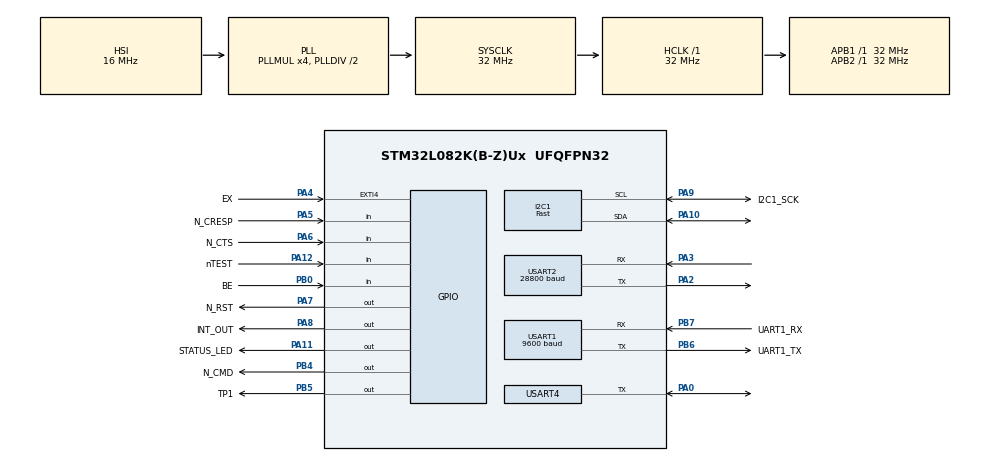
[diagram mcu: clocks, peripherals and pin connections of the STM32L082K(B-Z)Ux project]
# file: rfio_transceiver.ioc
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Dma.Request0=USART1_TX
Dma.Request1=USART1_RX
Dma.USART1_RX.1.Direction=DMA_PERIPH_TO_MEMORY
Dma.USART1_RX.1.Instance=DMA1_Channel3
Dma.USART1_RX.1.MemDataAlignment=DMA_MDATAALIGN_BYTE
Dma.USART1_RX.1.MemInc=DMA_MINC_ENABLE
Dma.USART1_RX.1.Mode=DMA_CIRCULAR
Dma.USART1_RX.1.PeriphDataAlignment=DMA_PDATAALIGN_BYTE
Dma.USART1_RX.1.PeriphInc=DMA_PINC_DISABLE
Dma.USART1_RX.1.Priority=DMA_PRIORITY_LOW
Dma.USART1_TX.0.Direction=DMA_MEMORY_TO_PERIPH
Dma.USART1_TX.0.Instance=DMA1_Channel2
Dma.USART1_TX.0.MemDataAlignment=DMA_MDATAALIGN_BYTE
Dma.USART1_TX.0.MemInc=DMA_MINC_ENABLE
Dma.USART1_TX.0.Mode=DMA_NORMAL
Dma.USART1_TX.0.PeriphDataAlignment=DMA_PDATAALIGN_BYTE
Dma.USART1_TX.0.PeriphInc=DMA_PINC_DISABLE
Dma.USART1_TX.0.Priority=DMA_PRIORITY_LOW
I2C1.DualAddressMode=I2C_DUALADDRESS_ENABLE
I2C1.I2C_Speed_Mode=I2C_Fast
I2C1.OwnAddress=PRIMARY_SLAVE_ADDR
I2C1.OwnAddress2=ENUM_SLAVE_ADDR
I2C1.Timing=0x00300F38
IWDG.Prescaler=IWDG_PRESCALER_256
Mcu.Family=STM32L0
Mcu.Name=STM32L082K(B-Z)Ux
Mcu.Package=UFQFPN32
Mcu.UserConstants=ENUM_SLAVE_ADDR,0x7F;PRIMARY_SLAVE_ADDR,0x44
NVIC.DMA1_Channel2_3_IRQn=true\:0\:0\:false\:false\:true\:false\:true\:true
NVIC.EXTI4_15_IRQn=true\:1\:0\:true\:false\:true\:true\:true\:true
NVIC.I2C1_IRQn=true\:0\:0\:false\:false\:true\:true\:true\:true
NVIC.TIM21_IRQn=true\:0\:0\:false\:false\:true\:true\:true\:true
NVIC.TIM2_IRQn=true\:0\:0\:false\:false\:true\:true\:true\:true
NVIC.USART1_IRQn=true\:2\:0\:true\:false\:true\:true\:true\:true
NVIC.USART2_IRQn=true\:0\:0\:false\:false\:true\:true\:true\:true
NVIC.USART4_5_IRQn=true\:0\:0\:false\:false\:true\:true\:true\:true
PA0.GPIO_ModeDefaultOD=GPIO_MODE_AF_PP
PA0.GPIO_PuPdOD=GPIO_NOPULL
PA0.Mode=Half_duplex(single_wire_mode)
PA0.Signal=USART4_TX
PA10.Mode=I2C
PA10.Signal=I2C1_SDA
PA11.GPIO_Label=STATUS_LED
PA11.Signal=GPIO_Output
PA12.GPIO_Label=nTEST
PA12.Signal=GPIO_Input
PA13.GPIO_Label=STM_SWDIO
PA13.Mode=Serial_Wire
PA13.Signal=SYS_SWDIO
PA14.Mode=Serial_Wire
PA14.Signal=SYS_SWCLK
PA2.Mode=Asynchronous
PA2.Signal=USART2_TX
PA3.Mode=Asynchronous
PA3.Signal=USART2_RX
PA4.GPIO_Label=EX
PA4.Signal=GPXTI4
PA5.GPIO_Label=N_CRESP
PA5.Signal=GPIO_Input
PA6.GPIO_Label=N_CTS
PA6.Signal=GPIO_Input
PA7.GPIO_Label=N_RST
PA7.Signal=GPIO_Output
PA8.GPIO_Label=INT_OUT
PA8.Signal=GPIO_Output
PA9.GPIO_Label=I2C1_SCK
PA9.Mode=I2C
PA9.Signal=I2C1_SCL
PB0.GPIO_Label=BE
PB0.Signal=GPIO_Input
PB4.GPIO_Label=N_CMD
PB4.Signal=GPIO_Output
PB5.GPIO_Label=TP1
PB5.GPIO_Speed=GPIO_SPEED_FREQ_VERY_HIGH
PB5.Signal=GPIO_Output
PB6.GPIO_Label=UART1_TX
PB6.Mode=Asynchronous
PB6.Signal=USART1_TX
PB7.GPIO_Label=UART1_RX
PB7.Mode=Asynchronous
PB7.Signal=USART1_RX
ProjectManager.HeapSize=0x400
ProjectManager.StackSize=0x800
ProjectManager.TargetToolchain=STM32CubeIDE
RCC.AHBFreq_Value=32000000
RCC.APB1Freq_Value=32000000
RCC.APB1TimFreq_Value=32000000
RCC.APB2Freq_Value=32000000
RCC.APB2TimFreq_Value=32000000
RCC.HCLKFreq_Value=32000000
RCC.HSI16_VALUE=16000000
RCC.HSI48_VALUE=48000000
RCC.HSI_VALUE=16000000
RCC.LSE_VALUE=32768
RCC.MSIClockRange=RCC_MSIRANGE_6
RCC.MSI_VALUE=4194000
RCC.PLLMUL=RCC_PLLMUL_4
RCC.SYSCLKFreq_VALUE=32000000
RCC.SYSCLKSource=RCC_SYSCLKSOURCE_PLLCLK
RCC.VCOOutputFreq_Value=64000000
TIM2.Channel-Output\ Compare1\ No\ Output=TIM_CHANNEL_1
TIM2.Period=32000 - 1
TIM21.Channel-Output\ Compare1\ No\ Output=TIM_CHANNEL_1
TIM21.Period=3333 - 1
USART1.BaudRate=9600
USART1.VirtualMode-Asynchronous=VM_ASYNC
USART2.BaudRate=28800
USART2.VirtualMode-Asynchronous=VM_ASYNC
USART4.VirtualMode=VM_ASYNC
VP_CRC_VS_CRC.Mode=CRC_Activate
VP_IWDG_VS_IWDG.Mode=IWDG_Activate
VP_TIM21_VS_ClockSourceINT.Mode=Internal
VP_TIM21_VS_no_output1.Mode=Output Compare1 No Output
VP_TIM2_VS_ClockSourceINT.Mode=Internal
VP_TIM2_VS_no_output1.Mode=Output Compare1 No Output
board=custom

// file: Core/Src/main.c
/* USER CODE BEGIN Header */
/**
  ******************************************************************************
  * @file           : main.c
  * @brief          : Main program body
  ******************************************************************************
  * @attention
  *
  * Copyright (c) 2025 STMicroelectronics.
  * All rights reserved.
  *
  * This software is licensed under terms that can be found in the LICENSE file
  * in the root directory of this software component.
  * If no LICENSE file comes with this software, it is provided AS-IS.
  *
  ******************************************************************************
  */
/* USER CODE END Header */
#include "main.h"

/* USER CODE BEGIN Includes */
#include "rfio_driver.h"
#include "Scheduler/Scheduler.h"
#include "Module_Bus_Driver.h"
/* USER CODE END Includes */

CRC_HandleTypeDef hcrc;

I2C_HandleTypeDef hi2c1;

IWDG_HandleTypeDef hiwdg;

TIM_HandleTypeDef htim2;
TIM_HandleTypeDef htim21;

UART_HandleTypeDef huart1;
UART_HandleTypeDef huart2;
UART_HandleTypeDef huart4;
DMA_HandleTypeDef hdma_usart1_tx;
DMA_HandleTypeDef hdma_usart1_rx;

/* USER CODE BEGIN PV */
const Firmware_Version FWVer = {1, 0, 0, 0};
const uint8_t Primary_Slave_Addr = PRIMARY_SLAVE_ADDR;
/* USER CODE END PV */

void SystemClock_Config(void);
static void MX_GPIO_Init(void);
static void MX_DMA_Init(void);
static void MX_CRC_Init(void);
static void MX_I2C1_Init(void);
static void MX_IWDG_Init(void);
static void MX_TIM2_Init(void);
static void MX_TIM21_Init(void);
static void MX_USART2_UART_Init(void);
static void MX_USART1_UART_Init(void);
static void MX_USART4_UART_Init(void);

int main(void)
{

  /* MCU Configuration--------------------------------------------------------*/

  /* Reset of all peripherals, Initializes the Flash interface and the Systick. */
  HAL_Init();

  /* Configure the system clock */
  SystemClock_Config();

  /* Initialize all configured peripherals */
  MX_GPIO_Init();
  MX_DMA_Init();
  MX_CRC_Init();
  MX_I2C1_Init();
  MX_IWDG_Init();
  MX_TIM2_Init();
  MX_TIM21_Init();
  MX_USART2_UART_Init();
  MX_USART1_UART_Init();
  MX_USART4_UART_Init();
  /* USER CODE BEGIN 2 */
  Start_Scheduler();
  Init_RFIO();
  HAL_TIM_Base_Start_IT(&htim2);
  HAL_TIM_Base_Start_IT(&htim21);
  /* USER CODE END 2 */

  /* Infinite loop */
  while (1)
  {
    Run_Scheduler_Tasks();
    Module_Bus_Tasks();
  }
}

void SystemClock_Config(void)
{
  RCC_OscInitTypeDef RCC_OscInitStruct = {0};
  RCC_ClkInitTypeDef RCC_ClkInitStruct = {0};
  RCC_PeriphCLKInitTypeDef PeriphClkInit = {0};

  /** Configure the main internal regulator output voltage
  */
  __HAL_PWR_VOLTAGESCALING_CONFIG(PWR_REGULATOR_VOLTAGE_SCALE1);

  /** Initializes the RCC Oscillators according to the specified parameters
  * in the RCC_OscInitTypeDef structure.
  */
  RCC_OscInitStruct.OscillatorType = RCC_OSCILLATORTYPE_HSI|RCC_OSCILLATORTYPE_LSI;
  RCC_OscInitStruct.HSIState = RCC_HSI_ON;
  RCC_OscInitStruct.HSICalibrationValue = RCC_HSICALIBRATION_DEFAULT;
  RCC_OscInitStruct.LSIState = RCC_LSI_ON;
  RCC_OscInitStruct.PLL.PLLState = RCC_PLL_ON;
  RCC_OscInitStruct.PLL.PLLSource = RCC_PLLSOURCE_HSI;
  RCC_OscInitStruct.PLL.PLLMUL = RCC_PLLMUL_4;
  RCC_OscInitStruct.PLL.PLLDIV = RCC_PLLDIV_2;
  if (HAL_RCC_OscConfig(&RCC_OscInitStruct) != HAL_OK)
  {
    Error_Handler();
  }

  /** Initializes the CPU, AHB and APB buses clocks
  */
  RCC_ClkInitStruct.ClockType = RCC_CLOCKTYPE_HCLK|RCC_CLOCKTYPE_SYSCLK
                              |RCC_CLOCKTYPE_PCLK1|RCC_CLOCKTYPE_PCLK2;
  RCC_ClkInitStruct.SYSCLKSource = RCC_SYSCLKSOURCE_PLLCLK;
  RCC_ClkInitStruct.AHBCLKDivider = RCC_SYSCLK_DIV1;
  RCC_ClkInitStruct.APB1CLKDivider = RCC_HCLK_DIV1;
  RCC_ClkInitStruct.APB2CLKDivider = RCC_HCLK_DIV1;

  if (HAL_RCC_ClockConfig(&RCC_ClkInitStruct, FLASH_LATENCY_1) != HAL_OK)
  {
    Error_Handler();
  }
  PeriphClkInit.PeriphClockSelection = RCC_PERIPHCLK_USART1|RCC_PERIPHCLK_USART2
                              |RCC_PERIPHCLK_I2C1;
  PeriphClkInit.Usart1ClockSelection = RCC_USART1CLKSOURCE_PCLK2;
  PeriphClkInit.Usart2ClockSelection = RCC_USART2CLKSOURCE_PCLK1;
  PeriphClkInit.I2c1ClockSelection = RCC_I2C1CLKSOURCE_PCLK1;
  if (HAL_RCCEx_PeriphCLKConfig(&PeriphClkInit) != HAL_OK)
  {
    Error_Handler();
  }
}

static void MX_CRC_Init(void)
{

  hcrc.Instance = CRC;
  hcrc.Init.DefaultPolynomialUse = DEFAULT_POLYNOMIAL_ENABLE;
  hcrc.Init.DefaultInitValueUse = DEFAULT_INIT_VALUE_ENABLE;
  hcrc.Init.InputDataInversionMode = CRC_INPUTDATA_INVERSION_NONE;
  hcrc.Init.OutputDataInversionMode = CRC_OUTPUTDATA_INVERSION_DISABLE;
  hcrc.InputDataFormat = CRC_INPUTDATA_FORMAT_BYTES;
  if (HAL_CRC_Init(&hcrc) != HAL_OK)
  {
    Error_Handler();
  }

}

static void MX_I2C1_Init(void)
{

  hi2c1.Instance = I2C1;
  hi2c1.Init.Timing = 0x00300F38;
  hi2c1.Init.OwnAddress1 = 136;
  hi2c1.Init.AddressingMode = I2C_ADDRESSINGMODE_7BIT;
  hi2c1.Init.DualAddressMode = I2C_DUALADDRESS_ENABLE;
  hi2c1.Init.OwnAddress2 = 254;
  hi2c1.Init.OwnAddress2Masks = I2C_OA2_NOMASK;
  hi2c1.Init.GeneralCallMode = I2C_GENERALCALL_DISABLE;
  hi2c1.Init.NoStretchMode = I2C_NOSTRETCH_DISABLE;
  if (HAL_I2C_Init(&hi2c1) != HAL_OK)
  {
    Error_Handler();
  }

  /** Configure Analogue filter
  */
  if (HAL_I2CEx_ConfigAnalogFilter(&hi2c1, I2C_ANALOGFILTER_ENABLE) != HAL_OK)
  {
    Error_Handler();
  }

  /** Configure Digital filter
  */
  if (HAL_I2CEx_ConfigDigitalFilter(&hi2c1, 0) != HAL_OK)
  {
    Error_Handler();
  }

}

static void MX_IWDG_Init(void)
{

  hiwdg.Instance = IWDG;
  hiwdg.Init.Prescaler = IWDG_PRESCALER_256;
  hiwdg.Init.Window = 4095;
  hiwdg.Init.Reload = 4095;
  if (HAL_IWDG_Init(&hiwdg) != HAL_OK)
  {
    Error_Handler();
  }

}

static void MX_TIM2_Init(void)
{

  TIM_ClockConfigTypeDef sClockSourceConfig = {0};
  TIM_MasterConfigTypeDef sMasterConfig = {0};
  TIM_OC_InitTypeDef sConfigOC = {0};

  htim2.Instance = TIM2;
  htim2.Init.Prescaler = 0;
  htim2.Init.CounterMode = TIM_COUNTERMODE_UP;
  htim2.Init.Period = 32000 - 1;
  htim2.Init.ClockDivision = TIM_CLOCKDIVISION_DIV1;
  htim2.Init.AutoReloadPreload = TIM_AUTORELOAD_PRELOAD_DISABLE;
  if (HAL_TIM_Base_Init(&htim2) != HAL_OK)
  {
    Error_Handler();
  }
  sClockSourceConfig.ClockSource = TIM_CLOCKSOURCE_INTERNAL;
  if (HAL_TIM_ConfigClockSource(&htim2, &sClockSourceConfig) != HAL_OK)
  {
    Error_Handler();
  }
  if (HAL_TIM_OC_Init(&htim2) != HAL_OK)
  {
    Error_Handler();
  }
  sMasterConfig.MasterOutputTrigger = TIM_TRGO_RESET;
  sMasterConfig.MasterSlaveMode = TIM_MASTERSLAVEMODE_DISABLE;
  if (HAL_TIMEx_MasterConfigSynchronization(&htim2, &sMasterConfig) != HAL_OK)
  {
    Error_Handler();
  }
  sConfigOC.OCMode = TIM_OCMODE_TIMING;
  sConfigOC.Pulse = 0;
  sConfigOC.OCPolarity = TIM_OCPOLARITY_HIGH;
  sConfigOC.OCFastMode = TIM_OCFAST_DISABLE;
  if (HAL_TIM_OC_ConfigChannel(&htim2, &sConfigOC, TIM_CHANNEL_1) != HAL_OK)
  {
    Error_Handler();
  }

}

static void MX_TIM21_Init(void)
{

  TIM_ClockConfigTypeDef sClockSourceConfig = {0};
  TIM_MasterConfigTypeDef sMasterConfig = {0};
  TIM_OC_InitTypeDef sConfigOC = {0};

  htim21.Instance = TIM21;
  htim21.Init.Prescaler = 0;
  htim21.Init.CounterMode = TIM_COUNTERMODE_UP;
  htim21.Init.Period = 3333 - 1;
  htim21.Init.ClockDivision = TIM_CLOCKDIVISION_DIV1;
  htim21.Init.AutoReloadPreload = TIM_AUTORELOAD_PRELOAD_DISABLE;
  if (HAL_TIM_Base_Init(&htim21) != HAL_OK)
  {
    Error_Handler();
  }
  sClockSourceConfig.ClockSource = TIM_CLOCKSOURCE_INTERNAL;
  if (HAL_TIM_ConfigClockSource(&htim21, &sClockSourceConfig) != HAL_OK)
  {
    Error_Handler();
  }
  if (HAL_TIM_OC_Init(&htim21) != HAL_OK)
  {
    Error_Handler();
  }
  sMasterConfig.MasterOutputTrigger = TIM_TRGO_RESET;
  sMasterConfig.MasterSlaveMode = TIM_MASTERSLAVEMODE_DISABLE;
  if (HAL_TIMEx_MasterConfigSynchronization(&htim21, &sMasterConfig) != HAL_OK)
  {
    Error_Handler();
  }
  sConfigOC.OCMode = TIM_OCMODE_TIMING;
  sConfigOC.Pulse = 0;
  sConfigOC.OCPolarity = TIM_OCPOLARITY_HIGH;
  sConfigOC.OCFastMode = TIM_OCFAST_DISABLE;
  if (HAL_TIM_OC_ConfigChannel(&htim21, &sConfigOC, TIM_CHANNEL_1) != HAL_OK)
  {
    Error_Handler();
  }

}

static void MX_USART1_UART_Init(void)
{

  huart1.Instance = USART1;
  huart1.Init.BaudRate = 9600;
  huart1.Init.WordLength = UART_WORDLENGTH_8B;
  huart1.Init.StopBits = UART_STOPBITS_1;
  huart1.Init.Parity = UART_PARITY_NONE;
  huart1.Init.Mode = UART_MODE_TX_RX;
  huart1.Init.HwFlowCtl = UART_HWCONTROL_NONE;
  huart1.Init.OverSampling = UART_OVERSAMPLING_16;
  huart1.Init.OneBitSampling = UART_ONE_BIT_SAMPLE_DISABLE;
  huart1.AdvancedInit.AdvFeatureInit = UART_ADVFEATURE_NO_INIT;
  if (HAL_UART_Init(&huart1) != HAL_OK)
  {
    Error_Handler();
  }

}

static void MX_USART2_UART_Init(void)
{

  huart2.Instance = USART2;
  huart2.Init.BaudRate = 28800;
  huart2.Init.WordLength = UART_WORDLENGTH_8B;
  huart2.Init.StopBits = UART_STOPBITS_1;
  huart2.Init.Parity = UART_PARITY_NONE;
  huart2.Init.Mode = UART_MODE_TX_RX;
  huart2.Init.HwFlowCtl = UART_HWCONTROL_NONE;
  huart2.Init.OverSampling = UART_OVERSAMPLING_16;
  huart2.Init.OneBitSampling = UART_ONE_BIT_SAMPLE_DISABLE;
  huart2.AdvancedInit.AdvFeatureInit = UART_ADVFEATURE_NO_INIT;
  if (HAL_UART_Init(&huart2) != HAL_OK)
  {
    Error_Handler();
  }

}

static void MX_USART4_UART_Init(void)
{

  huart4.Instance = USART4;
  huart4.Init.BaudRate = 115200;
  huart4.Init.WordLength = UART_WORDLENGTH_8B;
  huart4.Init.StopBits = UART_STOPBITS_1;
  huart4.Init.Parity = UART_PARITY_NONE;
  huart4.Init.Mode = UART_MODE_TX_RX;
  huart4.Init.HwFlowCtl = UART_HWCONTROL_NONE;
  huart4.Init.OverSampling = UART_OVERSAMPLING_16;
  huart4.Init.OneBitSampling = UART_ONE_BIT_SAMPLE_DISABLE;
  huart4.AdvancedInit.AdvFeatureInit = UART_ADVFEATURE_NO_INIT;
  if (HAL_HalfDuplex_Init(&huart4) != HAL_OK)
  {
    Error_Handler();
  }

}

static void MX_DMA_Init(void)
{

  /* DMA controller clock enable */
  __HAL_RCC_DMA1_CLK_ENABLE();

  /* DMA interrupt init */
  /* DMA1_Channel2_3_IRQn interrupt configuration */
  HAL_NVIC_SetPriority(DMA1_Channel2_3_IRQn, 0, 0);
  HAL_NVIC_EnableIRQ(DMA1_Channel2_3_IRQn);

}

static void MX_GPIO_Init(void)
{
  GPIO_InitTypeDef GPIO_InitStruct = {0};

  /* GPIO Ports Clock Enable */
  __HAL_RCC_GPIOA_CLK_ENABLE();
  __HAL_RCC_GPIOB_CLK_ENABLE();

  /*Configure GPIO pin Output Level */
  HAL_GPIO_WritePin(GPIOA, N_RST_Pin|INT_OUT_Pin|STATUS_LED_Pin, GPIO_PIN_RESET);

  /*Configure GPIO pin Output Level */
  HAL_GPIO_WritePin(GPIOB, N_CMD_Pin|TP1_Pin, GPIO_PIN_RESET);

  /*Configure GPIO pin : EX_Pin */
  GPIO_InitStruct.Pin = EX_Pin;
  GPIO_InitStruct.Mode = GPIO_MODE_IT_RISING;
  GPIO_InitStruct.Pull = GPIO_NOPULL;
  HAL_GPIO_Init(EX_GPIO_Port, &GPIO_InitStruct);

  /*Configure GPIO pins : N_CRESP_Pin N_CTS_Pin nTEST_Pin */
  GPIO_InitStruct.Pin = N_CRESP_Pin|N_CTS_Pin|nTEST_Pin;
  GPIO_InitStruct.Mode = GPIO_MODE_INPUT;
  GPIO_InitStruct.Pull = GPIO_NOPULL;
  HAL_GPIO_Init(GPIOA, &GPIO_InitStruct);

  /*Configure GPIO pins : N_RST_Pin INT_OUT_Pin STATUS_LED_Pin */
  GPIO_InitStruct.Pin = N_RST_Pin|INT_OUT_Pin|STATUS_LED_Pin;
  GPIO_InitStruct.Mode = GPIO_MODE_OUTPUT_PP;
  GPIO_InitStruct.Pull = GPIO_NOPULL;
  GPIO_InitStruct.Speed = GPIO_SPEED_FREQ_LOW;
  HAL_GPIO_Init(GPIOA, &GPIO_InitStruct);

  /*Configure GPIO pin : BE_Pin */
  GPIO_InitStruct.Pin = BE_Pin;
  GPIO_InitStruct.Mode = GPIO_MODE_INPUT;
  GPIO_InitStruct.Pull = GPIO_NOPULL;
  HAL_GPIO_Init(BE_GPIO_Port, &GPIO_InitStruct);

  /*Configure GPIO pin : N_CMD_Pin */
  GPIO_InitStruct.Pin = N_CMD_Pin;
  GPIO_InitStruct.Mode = GPIO_MODE_OUTPUT_PP;
  GPIO_InitStruct.Pull = GPIO_NOPULL;
  GPIO_InitStruct.Speed = GPIO_SPEED_FREQ_LOW;
  HAL_GPIO_Init(N_CMD_GPIO_Port, &GPIO_InitStruct);

  /*Configure GPIO pin : TP1_Pin */
  GPIO_InitStruct.Pin = TP1_Pin;
  GPIO_InitStruct.Mode = GPIO_MODE_OUTPUT_PP;
  GPIO_InitStruct.Pull = GPIO_NOPULL;
  GPIO_InitStruct.Speed = GPIO_SPEED_FREQ_VERY_HIGH;
  HAL_GPIO_Init(TP1_GPIO_Port, &GPIO_InitStruct);

  /* EXTI interrupt init*/
  HAL_NVIC_SetPriority(EXTI4_15_IRQn, 1, 0);
  HAL_NVIC_EnableIRQ(EXTI4_15_IRQn);

}

void Error_Handler(void)
{
  __disable_irq();
  while (1)
  {
  }
}
